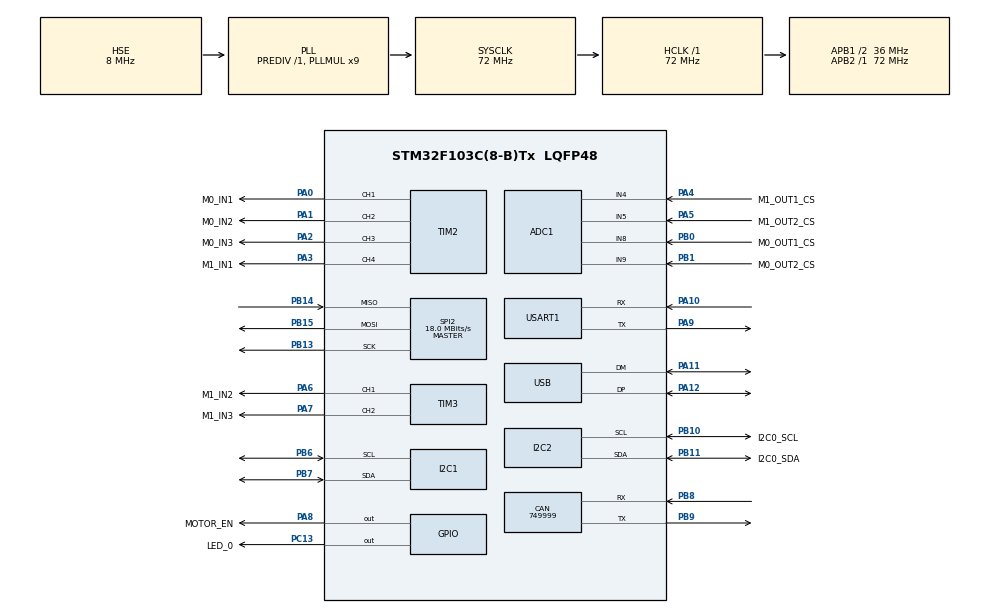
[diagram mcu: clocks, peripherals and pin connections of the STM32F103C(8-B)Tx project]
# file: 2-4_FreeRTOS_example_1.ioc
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ADC1.Channel-2\#ChannelRegularConversion=ADC_CHANNEL_4
ADC1.NbrOfConversionFlag=1
ADC1.Rank-2\#ChannelRegularConversion=1
ADC1.SamplingTime-2\#ChannelRegularConversion=ADC_SAMPLETIME_1CYCLE_5
ADC1.master=1
CAN.BS1=CAN_BS1_1TQ
CAN.BS2=CAN_BS2_1TQ
CAN.CalculateBaudRate=749999
CAN.CalculateTimeBit=1333
CAN.CalculateTimeQuantum=444.44444444444446
Dma.ADC1.2.Direction=DMA_PERIPH_TO_MEMORY
Dma.ADC1.2.Instance=DMA1_Channel1
Dma.ADC1.2.MemDataAlignment=DMA_MDATAALIGN_HALFWORD
Dma.ADC1.2.MemInc=DMA_MINC_ENABLE
Dma.ADC1.2.Mode=DMA_NORMAL
Dma.ADC1.2.PeriphDataAlignment=DMA_PDATAALIGN_HALFWORD
Dma.ADC1.2.PeriphInc=DMA_PINC_DISABLE
Dma.ADC1.2.Priority=DMA_PRIORITY_LOW
Dma.Request0=USART1_RX
Dma.Request1=USART1_TX
Dma.Request2=ADC1
Dma.USART1_RX.0.Direction=DMA_PERIPH_TO_MEMORY
Dma.USART1_RX.0.Instance=DMA1_Channel5
Dma.USART1_RX.0.MemDataAlignment=DMA_MDATAALIGN_BYTE
Dma.USART1_RX.0.MemInc=DMA_MINC_ENABLE
Dma.USART1_RX.0.Mode=DMA_CIRCULAR
Dma.USART1_RX.0.PeriphDataAlignment=DMA_PDATAALIGN_BYTE
Dma.USART1_RX.0.PeriphInc=DMA_PINC_DISABLE
Dma.USART1_RX.0.Priority=DMA_PRIORITY_LOW
Dma.USART1_TX.1.Direction=DMA_MEMORY_TO_PERIPH
Dma.USART1_TX.1.Instance=DMA1_Channel4
Dma.USART1_TX.1.MemDataAlignment=DMA_MDATAALIGN_BYTE
Dma.USART1_TX.1.MemInc=DMA_MINC_ENABLE
Dma.USART1_TX.1.Mode=DMA_NORMAL
Dma.USART1_TX.1.PeriphDataAlignment=DMA_PDATAALIGN_BYTE
Dma.USART1_TX.1.PeriphInc=DMA_PINC_DISABLE
Dma.USART1_TX.1.Priority=DMA_PRIORITY_LOW
FREERTOS.Tasks01=defaultTask,8,256,StartDefaultTask,Default,NULL,Dynamic,NULL,NULL;myTask01,8,256,myFunc01,Default,NULL,Dynamic,NULL,NULL;myTask02,8,128,myFunc02,Default,NULL,Dynamic,NULL,NULL
Mcu.Family=STM32F1
Mcu.Name=STM32F103C(8-B)Tx
Mcu.Package=LQFP48
NVIC.DMA1_Channel1_IRQn=true\:5\:0\:false\:false\:true\:true\:false\:true\:true
NVIC.DMA1_Channel4_IRQn=true\:5\:0\:false\:false\:true\:true\:false\:true\:true
NVIC.DMA1_Channel5_IRQn=true\:5\:0\:false\:false\:true\:true\:false\:true\:true
NVIC.PriorityGroup=NVIC_PRIORITYGROUP_4
NVIC.TIM2_IRQn=true\:5\:0\:false\:false\:true\:true\:true\:true\:true
NVIC.TIM4_IRQn=true\:15\:0\:false\:false\:true\:false\:false\:true\:true
NVIC.TimeBase=TIM4_IRQn
NVIC.TimeBaseIP=TIM4
NVIC.USART1_IRQn=true\:5\:0\:false\:false\:true\:true\:true\:true\:true
PA0-WKUP.GPIO_Label=M0_IN1
PA0-WKUP.Signal=S_TIM2_CH1_ETR
PA1.GPIO_Label=M0_IN2
PA1.Signal=S_TIM2_CH2
PA10.Mode=Asynchronous
PA10.Signal=USART1_RX
PA11.Mode=Device
PA11.Signal=USB_DM
PA12.Mode=Device
PA12.Signal=USB_DP
PA13.Mode=Serial_Wire
PA13.Signal=SYS_JTMS-SWDIO
PA14.Mode=Serial_Wire
PA14.Signal=SYS_JTCK-SWCLK
PA2.GPIO_Label=M0_IN3
PA2.Signal=S_TIM2_CH3
PA3.GPIO_Label=M1_IN1
PA3.Signal=S_TIM2_CH4
PA4.GPIO_Label=M1_OUT1_CS
PA4.Signal=ADCx_IN4
PA5.GPIO_Label=M1_OUT2_CS
PA5.Signal=ADCx_IN5
PA6.GPIO_Label=M1_IN2
PA6.Signal=S_TIM3_CH1
PA7.GPIO_Label=M1_IN3
PA7.Signal=S_TIM3_CH2
PA8.GPIO_Label=MOTOR_EN
PA8.Signal=GPIO_Output
PA9.Mode=Asynchronous
PA9.Signal=USART1_TX
PB0.GPIO_Label=M0_OUT1_CS
PB0.Signal=ADCx_IN8
PB1.GPIO_Label=M0_OUT2_CS
PB1.Signal=ADCx_IN9
PB10.GPIO_Label=I2C0_SCL
PB10.Mode=I2C
PB10.Signal=I2C2_SCL
PB11.GPIO_Label=I2C0_SDA
PB11.Mode=I2C
PB11.Signal=I2C2_SDA
PB13.Mode=Full_Duplex_Master
PB13.Signal=SPI2_SCK
PB14.Mode=Full_Duplex_Master
PB14.Signal=SPI2_MISO
PB15.Mode=Full_Duplex_Master
PB15.Signal=SPI2_MOSI
PB6.Mode=I2C
PB6.Signal=I2C1_SCL
PB7.Mode=I2C
PB7.Signal=I2C1_SDA
PB8.Mode=CAN_Activate
PB8.Signal=CAN_RX
PB9.Mode=CAN_Activate
PB9.Signal=CAN_TX
PC13-TAMPER-RTC.GPIO_Label=LED_0
PC13-TAMPER-RTC.Signal=GPIO_Output
PC14-OSC32_IN.Mode=LSE-External-Oscillator
PC14-OSC32_IN.Signal=RCC_OSC32_IN
PC15-OSC32_OUT.Mode=LSE-External-Oscillator
PC15-OSC32_OUT.Signal=RCC_OSC32_OUT
PD0-OSC_IN.Mode=HSE-External-Oscillator
PD0-OSC_IN.Signal=RCC_OSC_IN
PD1-OSC_OUT.Mode=HSE-External-Oscillator
PD1-OSC_OUT.Signal=RCC_OSC_OUT
ProjectManager.HeapSize=0x400
ProjectManager.StackSize=0x400
ProjectManager.TargetToolchain=STM32CubeIDE
RCC.ADCPresc=RCC_ADCPCLK2_DIV6
RCC.AHBFreq_Value=72000000
RCC.APB1CLKDivider=RCC_HCLK_DIV2
RCC.APB1Freq_Value=36000000
RCC.APB1TimFreq_Value=72000000
RCC.APB2Freq_Value=72000000
RCC.APB2TimFreq_Value=72000000
RCC.HCLKFreq_Value=72000000
RCC.PLLMUL=RCC_PLL_MUL9
RCC.PLLSourceVirtual=RCC_PLLSOURCE_HSE
RCC.SYSCLKFreq_VALUE=72000000
RCC.SYSCLKSource=RCC_SYSCLKSOURCE_PLLCLK
RCC.USBFreq_Value=48000000
RCC.USBPrescaler=RCC_USBCLKSOURCE_PLL_DIV1_5
SH.ADCx_IN4.0=ADC1_IN4,IN4
SH.ADCx_IN5.0=ADC1_IN5,IN5
SH.ADCx_IN8.0=ADC1_IN8,IN8
SH.ADCx_IN9.0=ADC1_IN9,IN9
SH.S_TIM2_CH1_ETR.0=TIM2_CH1,PWM Generation1 CH1
SH.S_TIM2_CH2.0=TIM2_CH2,PWM Generation2 CH2
SH.S_TIM2_CH3.0=TIM2_CH3,PWM Generation3 CH3
SH.S_TIM2_CH4.0=TIM2_CH4,PWM Generation4 CH4
SH.S_TIM3_CH1.0=TIM3_CH1,PWM Generation1 CH1
SH.S_TIM3_CH2.0=TIM3_CH2,PWM Generation2 CH2
SPI2.CalculateBaudRate=18.0 MBits/s
SPI2.Direction=SPI_DIRECTION_2LINES
SPI2.Mode=SPI_MODE_MASTER
SPI2.VirtualType=VM_MASTER
TIM2.AutoReloadPreload=TIM_AUTORELOAD_PRELOAD_ENABLE
TIM2.Channel-PWM\ Generation1\ CH1=TIM_CHANNEL_1
TIM2.Channel-PWM\ Generation2\ CH2=TIM_CHANNEL_2
TIM2.Channel-PWM\ Generation3\ CH3=TIM_CHANNEL_3
TIM2.Channel-PWM\ Generation4\ CH4=TIM_CHANNEL_4
TIM2.CounterMode=TIM_COUNTERMODE_CENTERALIGNED1
TIM2.OCMode_PWM-PWM\ Generation1\ CH1=TIM_OCMODE_PWM1
TIM2.TIM_MasterOutputTrigger=TIM_TRGO_UPDATE
TIM3.AutoReloadPreload=TIM_AUTORELOAD_PRELOAD_ENABLE
TIM3.Channel-PWM\ Generation1\ CH1=TIM_CHANNEL_1
TIM3.Channel-PWM\ Generation2\ CH2=TIM_CHANNEL_2
TIM3.CounterMode=TIM_COUNTERMODE_CENTERALIGNED1
TIM3.TIM_MasterOutputTrigger=TIM_TRGO_UPDATE
USART1.VirtualMode=VM_ASYNC
VP_FREERTOS_VS_CMSIS_V2.Mode=CMSIS_V2
VP_SYS_VS_tim4.Mode=TIM4
VP_TIM1_VS_ClockSourceINT.Mode=Internal
VP_TIM2_VS_ClockSourceINT.Mode=Internal
VP_TIM3_VS_ClockSourceINT.Mode=Internal
board=custom

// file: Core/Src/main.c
/* USER CODE BEGIN Header */
/**
  ******************************************************************************
  * @file           : main.c
  * @brief          : Main program body
  ******************************************************************************
  * @attention
  *
  * Copyright (c) 2026 STMicroelectronics.
  * All rights reserved.
  *
  * This software is licensed under terms that can be found in the LICENSE file
  * in the root directory of this software component.
  * If no LICENSE file comes with this software, it is provided AS-IS.
  *
  ******************************************************************************
  */
/* USER CODE END Header */
#include "main.h"
#include "cmsis_os.h"
#include "adc.h"
#include "can.h"
#include "dma.h"
#include "i2c.h"
#include "spi.h"
#include "tim.h"
#include "usart.h"
#include "usb.h"
#include "gpio.h"

/* USER CODE BEGIN Includes */
#include "BSP_init.h"
#include "test_framework.h"
#include "user_task.h"
/* USER CODE END Includes */

void SystemClock_Config(void);
void MX_FREERTOS_Init(void);

int main(void)
{

  /* MCU Configuration--------------------------------------------------------*/

  /* Reset of all peripherals, Initializes the Flash interface and the Systick. */
  HAL_Init();

  /* Configure the system clock */
  SystemClock_Config();

  /* Initialize all configured peripherals */
  MX_GPIO_Init();
  MX_DMA_Init();
  MX_CAN_Init();
  MX_I2C1_Init();
  MX_TIM1_Init();
  MX_USART1_UART_Init();
  MX_I2C2_Init();
  MX_TIM2_Init();
  MX_TIM3_Init();
  MX_SPI2_Init();
  MX_USB_PCD_Init();
  MX_ADC1_Init();
  /* USER CODE BEGIN 2 */
  bsp_init();
  Test_Framework_Init();
  /* USER CODE END 2 */

  /* Init scheduler */
  osKernelInitialize();  /* Call init function for freertos objects (in cmsis_os2.c) */
  MX_FREERTOS_Init();

  /* Start scheduler */
  osKernelStart();

  /* We should never get here as control is now taken by the scheduler */

  /* Infinite loop */
  while (1)
  {

  }
}

void SystemClock_Config(void)
{
  RCC_OscInitTypeDef RCC_OscInitStruct = {0};
  RCC_ClkInitTypeDef RCC_ClkInitStruct = {0};
  RCC_PeriphCLKInitTypeDef PeriphClkInit = {0};

  /** Initializes the RCC Oscillators according to the specified parameters
  * in the RCC_OscInitTypeDef structure.
  */
  RCC_OscInitStruct.OscillatorType = RCC_OSCILLATORTYPE_HSE;
  RCC_OscInitStruct.HSEState = RCC_HSE_ON;
  RCC_OscInitStruct.HSEPredivValue = RCC_HSE_PREDIV_DIV1;
  RCC_OscInitStruct.HSIState = RCC_HSI_ON;
  RCC_OscInitStruct.PLL.PLLState = RCC_PLL_ON;
  RCC_OscInitStruct.PLL.PLLSource = RCC_PLLSOURCE_HSE;
  RCC_OscInitStruct.PLL.PLLMUL = RCC_PLL_MUL9;
  if (HAL_RCC_OscConfig(&RCC_OscInitStruct) != HAL_OK)
  {
    Error_Handler();
  }

  /** Initializes the CPU, AHB and APB buses clocks
  */
  RCC_ClkInitStruct.ClockType = RCC_CLOCKTYPE_HCLK|RCC_CLOCKTYPE_SYSCLK
                              |RCC_CLOCKTYPE_PCLK1|RCC_CLOCKTYPE_PCLK2;
  RCC_ClkInitStruct.SYSCLKSource = RCC_SYSCLKSOURCE_PLLCLK;
  RCC_ClkInitStruct.AHBCLKDivider = RCC_SYSCLK_DIV1;
  RCC_ClkInitStruct.APB1CLKDivider = RCC_HCLK_DIV2;
  RCC_ClkInitStruct.APB2CLKDivider = RCC_HCLK_DIV1;

  if (HAL_RCC_ClockConfig(&RCC_ClkInitStruct, FLASH_LATENCY_2) != HAL_OK)
  {
    Error_Handler();
  }
  PeriphClkInit.PeriphClockSelection = RCC_PERIPHCLK_ADC|RCC_PERIPHCLK_USB;
  PeriphClkInit.AdcClockSelection = RCC_ADCPCLK2_DIV6;
  PeriphClkInit.UsbClockSelection = RCC_USBCLKSOURCE_PLL_DIV1_5;
  if (HAL_RCCEx_PeriphCLKConfig(&PeriphClkInit) != HAL_OK)
  {
    Error_Handler();
  }
}

void HAL_TIM_PeriodElapsedCallback(TIM_HandleTypeDef *htim)
{
  if (htim->Instance == TIM4)
  {
    HAL_IncTick();
  }
}

void Error_Handler(void)
{
  __disable_irq();
  while (1)
  {
  }
}

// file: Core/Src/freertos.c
/* USER CODE BEGIN Header */
/**
  ******************************************************************************
  * File Name          : freertos.c
  * Description        : Code for freertos applications
  ******************************************************************************
  * @attention
  *
  * Copyright (c) 2026 STMicroelectronics.
  * All rights reserved.
  *
  * This software is licensed under terms that can be found in the LICENSE file
  * in the root directory of this software component.
  * If no LICENSE file comes with this software, it is provided AS-IS.
  *
  ******************************************************************************
  */
/* USER CODE END Header */

#include "FreeRTOS.h"
#include "task.h"
#include "main.h"
#include "cmsis_os.h"

/* Definitions for defaultTask */
osThreadId_t defaultTaskHandle;
const osThreadAttr_t defaultTask_attributes = {
  .name = "defaultTask",
  .stack_size = 256 * 4,
  .priority = (osPriority_t) osPriorityLow,
};
/* Definitions for myTask01 */
osThreadId_t myTask01Handle;
const osThreadAttr_t myTask01_attributes = {
  .name = "myTask01",
  .stack_size = 256 * 4,
  .priority = (osPriority_t) osPriorityLow,
};
/* Definitions for myTask02 */
osThreadId_t myTask02Handle;
const osThreadAttr_t myTask02_attributes = {
  .name = "myTask02",
  .stack_size = 128 * 4,
  .priority = (osPriority_t) osPriorityLow,
};

void StartDefaultTask(void *argument);
void myFunc01(void *argument);
void myFunc02(void *argument);

void MX_FREERTOS_Init(void); /* (MISRA C 2004 rule 8.1) */

void MX_FREERTOS_Init(void) {

  /* Create the thread(s) */
  /* creation of defaultTask */
  defaultTaskHandle = osThreadNew(StartDefaultTask, NULL, &defaultTask_attributes);

  /* creation of myTask01 */
  myTask01Handle = osThreadNew(myFunc01, NULL, &myTask01_attributes);

  /* creation of myTask02 */
  myTask02Handle = osThreadNew(myFunc02, NULL, &myTask02_attributes);

}

void StartDefaultTask(void *argument)
{
  for(;;)
  {
    osDelay(1);
  }
}

void myFunc01(void *argument)
{
  for(;;)
  {
    osDelay(1);
  }
}

void myFunc02(void *argument)
{
  for(;;)
  {
    osDelay(1);
  }
}
